# M4K4A register map
File version: 0.1
Registers are 32-bit, read-write, reset 0x0 unless marked. A register's access mark holds for its fields unless they carry their own. Offsets are from the block's base; [hi:lo] are bit positions; {n}, {i} and the like mark numbered series.

## PB — Port B
Base 0x400C0100
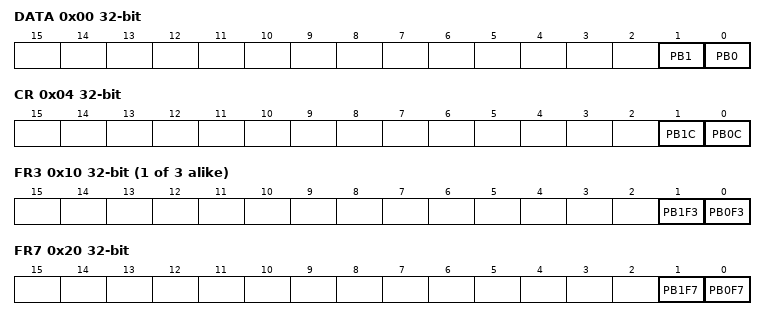
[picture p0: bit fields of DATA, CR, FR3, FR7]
0x00 DATA — PB Data Register
  [1] PB1, [0] PB0
0x04 CR — PB Control Register
  [1] PB1C, [0] PB0C
0x08 FR1 — PB Function Register 1
  [1] PB1F1
{0x4+4i} FR{i} (i=3..5) — PB Function Register {i}
  [1] PB1F{i}, [0] PB0F{i}
0x1C FR6 — PB Function Register 6
  [1] PB1F6
0x20 FR7 — PB Function Register 7
  [1] PB1F7, [0] PB0F7
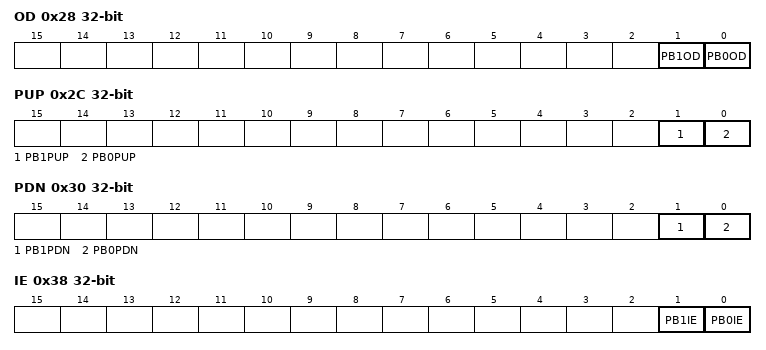
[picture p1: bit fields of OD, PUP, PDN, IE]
0x28 OD — PB Open Drain Control Register
  [1] PB1OD, [0] PB0OD
0x2C PUP — PB Pull-up Control Register
  [1] PB1PUP, [0] PB0PUP
0x30 PDN — PB Pull-Down Control Register
  [1] PB1PDN, [0] PB0PDN
0x38 IE — PB Input Enable Control Register
  [1] PB1IE, [0] PB0IE

## PC — Port C
Base 0x400C0200
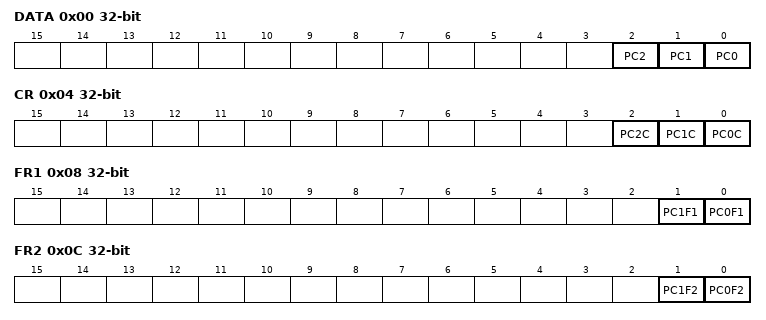
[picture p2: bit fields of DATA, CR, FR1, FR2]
0x00 DATA — PC Data Register
  [2] PC2, [1] PC1, [0] PC0
0x04 CR — PC Control Register
  [2] PC2C, [1] PC1C, [0] PC0C
0x08 FR1 — PC Function Register 1
  [1] PC1F1, [0] PC0F1
0x0C FR2 — PC Function Register 2
  [1] PC1F2, [0] PC0F2
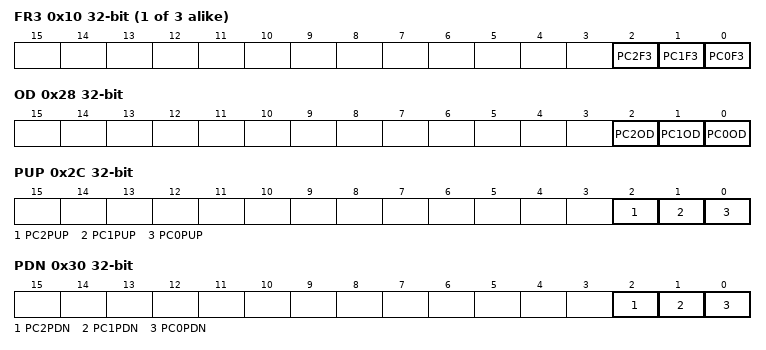
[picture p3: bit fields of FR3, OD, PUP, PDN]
{0x4+4i} FR{i} (i=3..5) — PC Function Register {i}
  [2] PC2F{i}, [1] PC1F{i}, [0] PC0F{i}
0x28 OD — PC Open Drain Control Register
  [2] PC2OD, [1] PC1OD, [0] PC0OD
0x2C PUP — PC Pull-up Control Register
  [2] PC2PUP, [1] PC1PUP, [0] PC0PUP
0x30 PDN — PC Pull-Down Control Register
  [2] PC2PDN, [1] PC1PDN, [0] PC0PDN
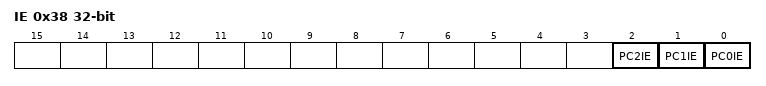
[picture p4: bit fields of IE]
0x38 IE — PC Input Enable Control Register
  [2] PC2IE, [1] PC1IE, [0] PC0IE

## PD — Port D
Base 0x400C0300
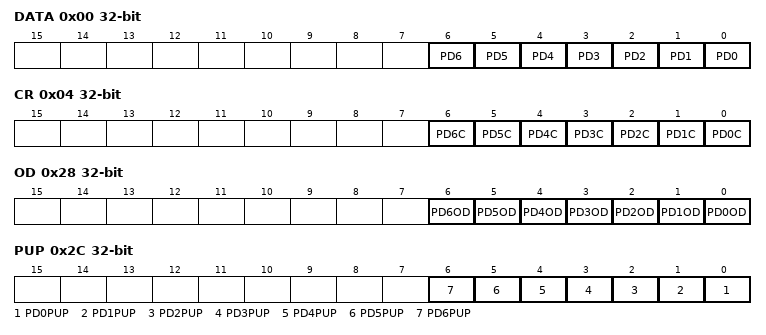
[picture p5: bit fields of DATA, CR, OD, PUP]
0x00 DATA — PD Data Register
  [n] PD{n} (n=0..6)
0x04 CR — PD Control Register
  [n] PD{n}C (n=0..6)
0x18 FR5 — PD Function Register 5
  [6] PD6F5
0x28 OD — PD Open Drain Control Register
  [n] PD{n}OD (n=0..6)
0x2C PUP — PD Pull-up Control Register
  [n] PD{n}PUP (n=0..6)
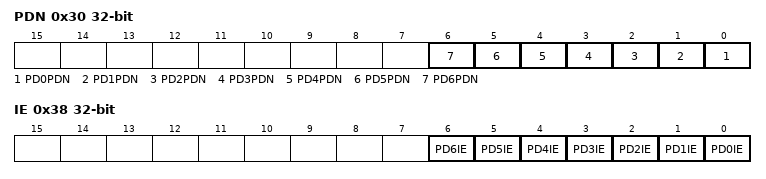
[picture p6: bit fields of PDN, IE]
0x30 PDN — PD Pull-Down Control Register
  [n] PD{n}PDN (n=0..6)
0x38 IE — PD Input Enable Control Register
  [n] PD{n}IE (n=0..6)

## PE — Port E
Base 0x400C0400
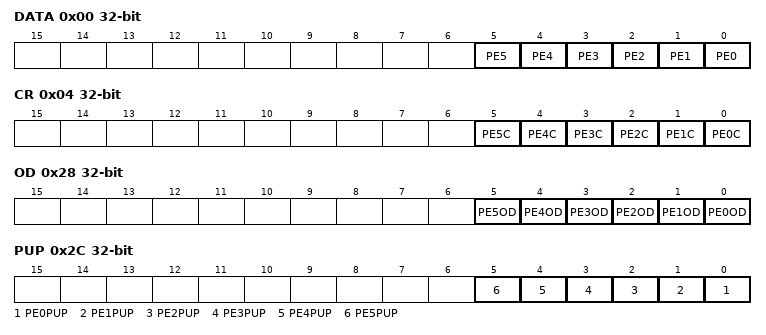
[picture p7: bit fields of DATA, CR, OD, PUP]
0x00 DATA — PE Data Register
  [n] PE{n} (n=0..5)
0x04 CR — PE Control Register
  [n] PE{n}C (n=0..5)
0x28 OD — PE Open Drain Control Register
  [n] PE{n}OD (n=0..5)
0x2C PUP — PE Pull-up Control Register
  [n] PE{n}PUP (n=0..5)
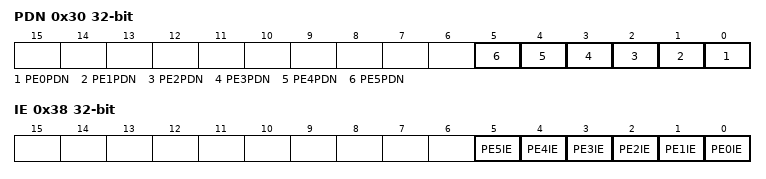
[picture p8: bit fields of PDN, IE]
0x30 PDN — PE Pull-Down Control Register
  [n] PE{n}PDN (n=0..5)
0x38 IE — PE Input Enable Control Register
  [n] PE{n}IE (n=0..5)

## PF
Base 0x400C0500
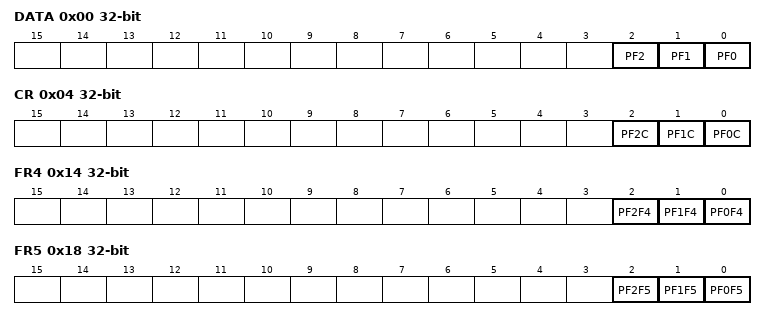
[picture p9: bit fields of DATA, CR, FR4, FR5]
0x00 DATA — PF Data Register
  [2] PF2, [1] PF1, [0] PF0
0x04 CR — PF Control Register
  [2] PF2C, [1] PF1C, [0] PF0C
0x14 FR4 — PF Function Register 4
  [2] PF2F4, [1] PF1F4, [0] PF0F4
0x18 FR5 — PF Function Register 5
  [2] PF2F5, [1] PF1F5, [0] PF0F5
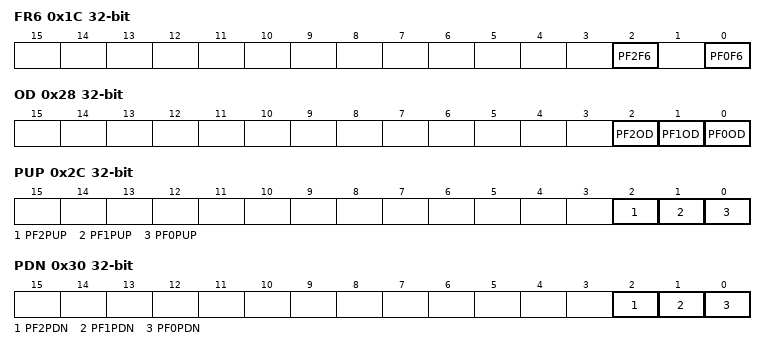
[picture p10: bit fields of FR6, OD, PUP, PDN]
0x1C FR6 — PF Function Register 6
  [2] PF2F6, [0] PF0F6
0x20 FR7 — PF Function Register 7
  [0] PF0F7
0x28 OD — PF Open Drain Control Register
  [2] PF2OD, [1] PF1OD, [0] PF0OD
0x2C PUP — PF Pull-up Control Register
  [2] PF2PUP, [1] PF1PUP, [0] PF0PUP
0x30 PDN — PF Pull-Down Control Register
  [2] PF2PDN, [1] PF1PDN, [0] PF0PDN
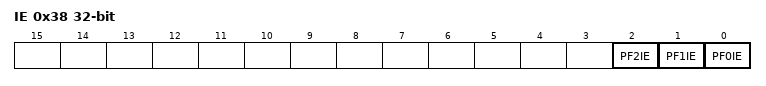
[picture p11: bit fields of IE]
0x38 IE — PF Input Enable Control Register
  [2] PF2IE, [1] PF1IE, [0] PF0IE

## PG
Base 0x400C0600
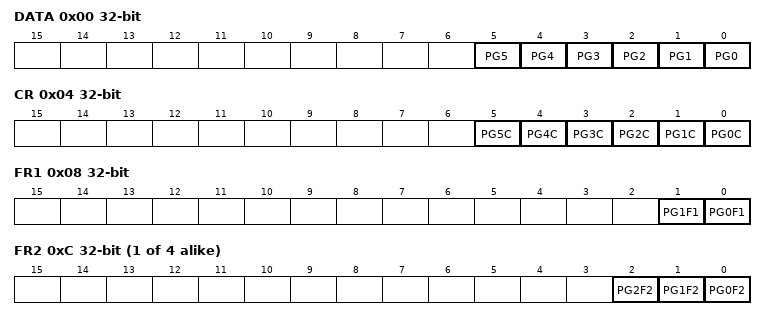
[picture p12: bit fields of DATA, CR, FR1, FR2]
0x00 DATA — PG Data Register
  [n] PG{n} (n=0..5)
0x04 CR — PG Control Register
  [n] PG{n}C (n=0..5)
0x08 FR1 — PG Function Register 1
  [1] PG1F1, [0] PG0F1
{0x4+4i} FR{i} (i=2..5) — PG Function Register {i}
  [2] PG2F{i}, [1] PG1F{i}, [0] PG0F{i}
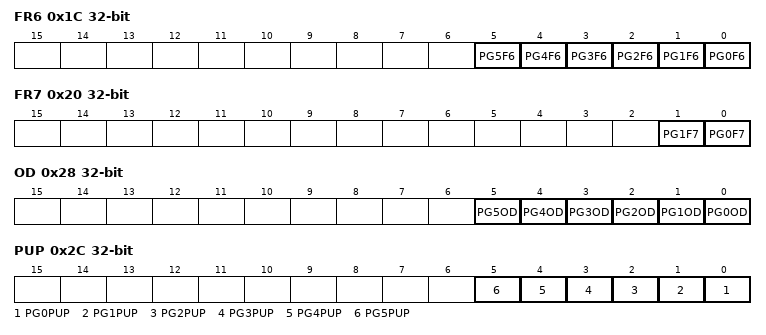
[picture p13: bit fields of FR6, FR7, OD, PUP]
0x1C FR6 — PG Function Register 6
  [n] PG{n}F6 (n=0..5)
0x20 FR7 — PG Function Register 7
  [1] PG1F7, [0] PG0F7
0x28 OD — PG Open Drain Control Register
  [n] PG{n}OD (n=0..5)
0x2C PUP — PG Pull-up Control Register
  [n] PG{n}PUP (n=0..5)
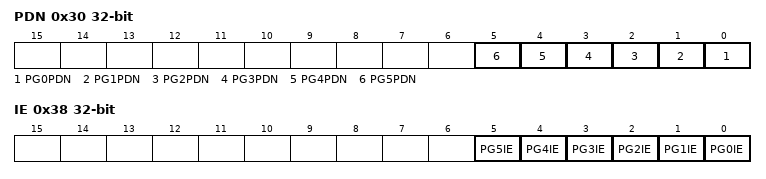
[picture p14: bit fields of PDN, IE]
0x30 PDN — PG Pull-Down Control Register
  [n] PG{n}PDN (n=0..5)
0x38 IE — PG Input Enable Control Register
  [n] PG{n}IE (n=0..5)

## PH
Base 0x400C0700
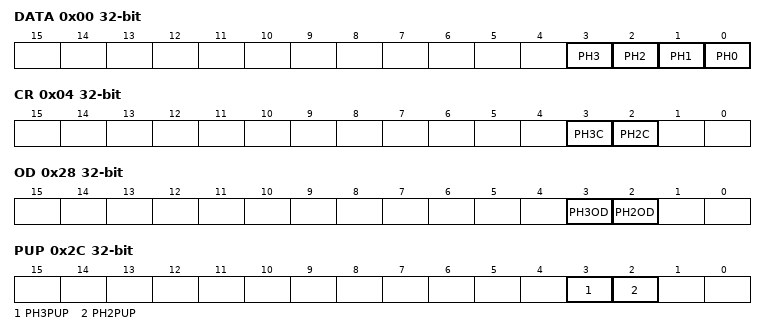
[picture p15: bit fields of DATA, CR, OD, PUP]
0x00 DATA — PH Data Register
  [n] PH{n} (n=0..3)
0x04 CR — PH Control Register
  [3] PH3C, [2] PH2C
0x18 FR5 — PH Function Register 5
  [2] PH2F5
0x28 OD — PH Open Drain Control Register
  [3] PH3OD, [2] PH2OD
0x2C PUP — PH Pull-up Control Register
  [3] PH3PUP, [2] PH2PUP
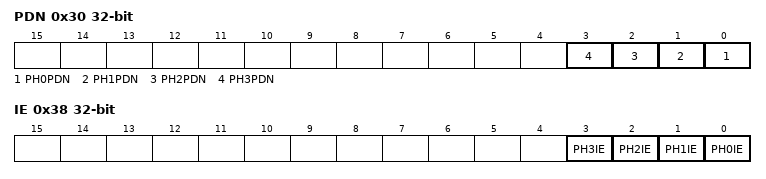
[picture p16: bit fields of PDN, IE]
0x30 PDN — PH Pull-Down Control Register
  [n] PH{n}PDN (n=0..3)
0x38 IE — PH Input Enable Control Register
  [n] PH{n}IE (n=0..3)
